# GD32E25x register map
File version: 1.0
CPU: CM23 r1p0, little endian, no MPU, no FPU, 2 interrupt priority bits
Registers are 32-bit, read-write, reset 0x0 unless marked. A register's access mark holds for its fields unless they carry their own. Offsets are from the block's base; [hi:lo] are bit positions; {n}, {i} and the like mark numbered series.

## PMU — Power management unit
Base 0x40007000
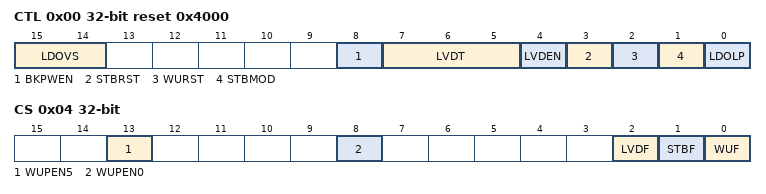
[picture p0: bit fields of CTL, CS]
0x00 CTL reset 0x4000 — power control register
  [15:14] LDOVS — LDO output voltage select
  [8] BKPWEN — Backup Domain Write Enable
  [7:5] LVDT — Low Voltage Detector Threshold
  [4] LVDEN — Low Voltage Detector Enable
  [3] STBRST — Standby Flag Reset
  [2] WURST — Wakeup Flag Reset
  [1] STBMOD — Standby Mode
  [0] LDOLP — LDO Low Power Mode
0x04 CS access per field — power control/status register
  [13] WUPEN5 rw — WKUP pin5 Enable
  [8] WUPEN0 rw — WKUP pin0 Enable
  [2] LVDF ro — Low Voltage Detector Status Flag
  [1] STBF ro — Standby flag
  [0] WUF ro — Wakeup flag
0x08 TEST
  [0] VSSBNCOE — VSS BOUNCE output enable

## RTC — Real-time clock
Base 0x40002800
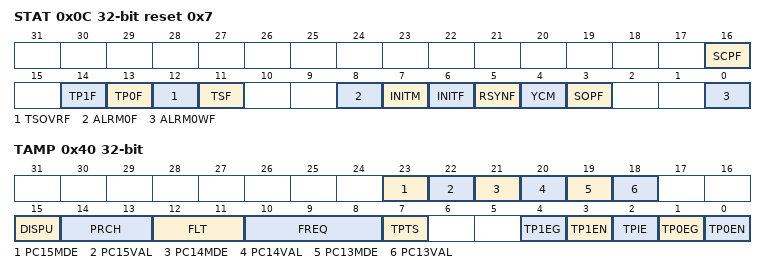
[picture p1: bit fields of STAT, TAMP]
0x0C STAT access per field reset 0x7 — initialization and status register
  [16] SCPF ro — Smooth calibration pending flag
  [14] TP1F rw — RTC_TAMP1 detection flag
  [13] TP0F rw — RTC_TAMP0 detection flag
  [12] TSOVRF rw — Time-stamp overflow flag
  [11] TSF rw — Time-stamp flag
  [8] ALRM0F rw — Alarm0 flag
  [7] INITM rw — Initialization mode
  [6] INITF ro — Initialization flag
  [5] RSYNF rw — Registers synchronization flag
  [4] YCM ro — Initialization status flag
  [3] SOPF ro — Shift operation pending
  [0] ALRM0WF ro — Alarm0 write flag
0x40 TAMP — tamper and alternate function configuration register
  [23] PC15MDE — PC15 mode
  [22] PC15VAL — PC15 value
  [21] PC14MDE — PC14 mode
  [20] PC14VAL — PC14 value
  [19] PC13MDE — PC13 mode
  [18] PC13VAL — RTC_ALARM output type/PC13 value
  [15] DISPU — RTC_TAMPx pull-up disable
  [14:13] PRCH — RTC_TAMPx precharge duration
  [12:11] FLT — RTC_TAMPx filter count
  [10:8] FREQ — Tamper sampling frequency
  [7] TPTS — Activate timestamp on tamper detection event
  [4] TP1EG — Tamper 1 event trigger edge
  [3] TP1EN — Tamper 1 detection enable
  [2] TPIE — Tamper detection interrupt enable
  [1] TP0EG — Active level for RTC_TAMP1 input
  [0] TP0EN — Tamper 0 event trigger edge
{0x50+4i} BKP{i} (i=0..4) — backup register
  [31:0] DATA — BKP data

## SPI0 — Serial peripheral interface
Base 0x40013000
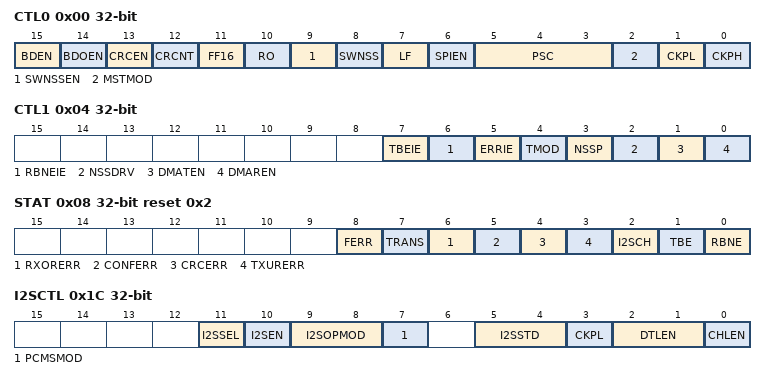
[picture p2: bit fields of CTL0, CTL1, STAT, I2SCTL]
0x00 CTL0 — control register 0
  [15] BDEN — Bidirectional enable
  [14] BDOEN — Bidirectional Transmit output enable
  [13] CRCEN — Hardware CRC calculation enable
  [12] CRCNT — CRC transfer next
  [11] FF16 — Data frame format
  [10] RO — Receive only
  [9] SWNSSEN — NSS Software Mode Selection
  [8] SWNSS — NSS Pin Selection In NSS Software Mode
  [7] LF — LSB First Mode
  [6] SPIEN — SPI enable
  [5:3] PSC — Master Clock Prescaler Selection
  [2] MSTMOD — Master Mode Enable
  [1] CKPL — Clock Polarity Selection
  [0] CKPH — Clock Phase Selection
0x04 CTL1 — control register 1
  [7] TBEIE — Transmit Buffer Empty Interrupt Enable
  [6] RBNEIE — Receive Buffer Not Empty Interrupt Enable
  [5] ERRIE — Error interrupt enable
  [4] TMOD — SPI TI Mode Enable
  [3] NSSP — SPI NSS Pulse Mode Enable
  [2] NSSDRV — NSS output enable
  [1] DMATEN — Tx buffer DMA enable
  [0] DMAREN — Rx buffer DMA enable
0x08 STAT access per field reset 0x2 — status register
  [8] FERR rw — Format Error
  [7] TRANS ro — Transmitting ongoing Bit
  [6] RXORERR ro — Reception Overrun Error Bit
  [5] CONFERR ro — SPI Configuration error
  [4] CRCERR rw — SPI CRC Error Bit
  [3] TXURERR ro — Transmission underrun error bit
  [2] I2SCH ro — I2S channel side
  [1] TBE ro — Transmit Buffer Empty
  [0] RBNE ro — Receive Buffer Not Empty
0x0C DATA
  [15:0] DATA
0x10 CPCPOLY reset 0x7 — CRC polynomial register
  [15:0] CRCPOLY
0x14 RCRC ro — RX CRC register
  [15:0] RCRC — RX RCR register
0x18 TCRC ro — TX CRC register
  [15:0] TCRC — Tx CRC register
0x1C I2SCTL — I2S configuration register
  [11] I2SSEL — I2S mode selection
  [10] I2SEN — I2S Enable
  [9:8] I2SOPMOD — I2S configuration mode
  [7] PCMSMOD — PCM frame synchronization
  [5:4] I2SSTD — I2S standard selection
  [3] CKPL — Idle state clock polarity
  [2:1] DTLEN — Data length to be transferred
  [0] CHLEN — Channel length (number of bits per audio channel)
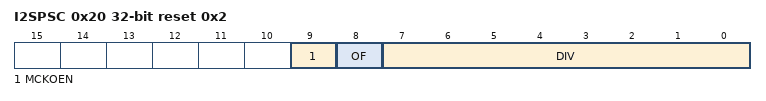
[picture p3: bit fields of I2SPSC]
0x20 I2SPSC reset 0x2 — I2S prescaler register
  [9] MCKOEN — I2S_MCK output enable
  [8] OF — Odd factor for the prescaler
  [7:0] DIV — Dividing factor for the prescaler
